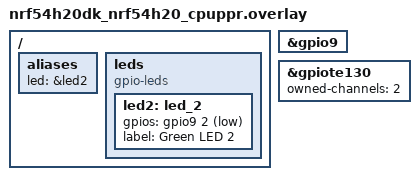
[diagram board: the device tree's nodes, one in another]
/*
 * Copyright (c) 2025 Nordic Semiconductor ASA
 *
 * SPDX-License-Identifier: LicenseRef-Nordic-5-Clause
 */

/ {
	aliases {
		led = &led2;
	};

	leds {
		compatible = "gpio-leds";

		/*
		 * Lilium pulls GPIOs up during bootup, to adapt
		 * to measurement methods, logic is inverted
		 */
		led2: led_2 {
			gpios = <&gpio9 2 GPIO_ACTIVE_LOW>;
			label = "Green LED 2";
		};
	};
};

&gpio9 {
	status = "okay";
};

&gpiote130 {
	status = "okay";
	owned-channels = <2>;
};
